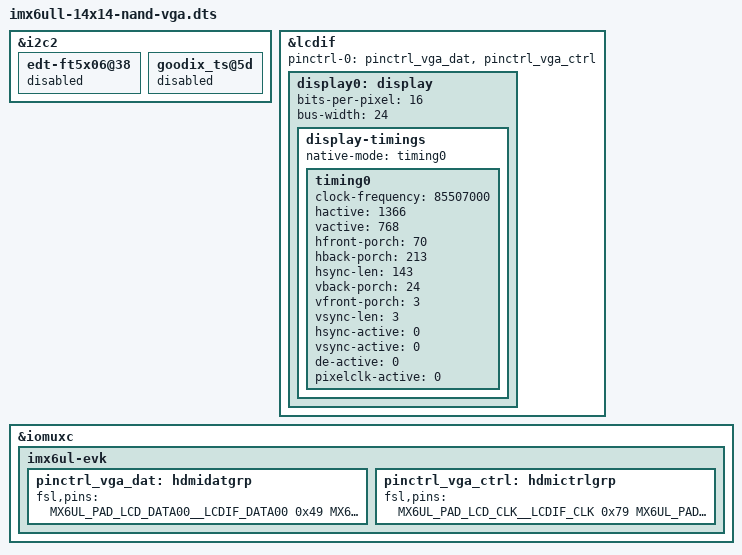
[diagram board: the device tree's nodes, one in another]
#include "imx6ull-14x14-evk-gpmi-weim.dts"

&i2c2 {
        edt-ft5x06@38 {
                status = "disabled";
        };

        goodix_ts@5d {
                status = "disabled";
        };
};

&lcdif {
        pinctrl-0 = <&pinctrl_vga_dat
                    &pinctrl_vga_ctrl>;

	display0: display {
		bits-per-pixel = <16>;
		bus-width = <24>;

		display-timings {
			native-mode = <&timing0>;
			timing0: timing0 {
                        clock-frequency = <85507000>;
                        hactive = <1366>;
                        vactive = <768>;
                        hfront-porch = <70>;
                        hback-porch = <213>;
                        hsync-len = <143>;
                        vback-porch = <24>;
                        vfront-porch = <3>;
                        vsync-len = <3>;

                        hsync-active = <0>;
                        vsync-active = <0>;
                        de-active = <0>;
                        pixelclk-active = <0>;
			};
		};
	};
};

&iomuxc {
	imx6ul-evk {
                pinctrl_vga_dat: hdmidatgrp {
                        fsl,pins = <
				/* do not change the pimux vlaue on alpaha and mini board*/
                                MX6UL_PAD_LCD_DATA00__LCDIF_DATA00  0x49
                                MX6UL_PAD_LCD_DATA01__LCDIF_DATA01  0x49
                                MX6UL_PAD_LCD_DATA02__LCDIF_DATA02  0x49
                                MX6UL_PAD_LCD_DATA03__LCDIF_DATA03  0x49
                                MX6UL_PAD_LCD_DATA04__LCDIF_DATA04  0x49
                                MX6UL_PAD_LCD_DATA05__LCDIF_DATA05  0x49
                                MX6UL_PAD_LCD_DATA06__LCDIF_DATA06  0x49
                                MX6UL_PAD_LCD_DATA07__LCDIF_DATA07  0x51
                                MX6UL_PAD_LCD_DATA08__LCDIF_DATA08  0x49
                                MX6UL_PAD_LCD_DATA09__LCDIF_DATA09  0x49
                                MX6UL_PAD_LCD_DATA10__LCDIF_DATA10  0x49
                                MX6UL_PAD_LCD_DATA11__LCDIF_DATA11  0x49
                                MX6UL_PAD_LCD_DATA12__LCDIF_DATA12  0x49
                                MX6UL_PAD_LCD_DATA13__LCDIF_DATA13  0x49
                                MX6UL_PAD_LCD_DATA14__LCDIF_DATA14  0x49
                                MX6UL_PAD_LCD_DATA15__LCDIF_DATA15  0x51
                                MX6UL_PAD_LCD_DATA16__LCDIF_DATA16  0x49
                                MX6UL_PAD_LCD_DATA17__LCDIF_DATA17  0x49
                                MX6UL_PAD_LCD_DATA18__LCDIF_DATA18  0x49
                                MX6UL_PAD_LCD_DATA19__LCDIF_DATA19  0x49
                                MX6UL_PAD_LCD_DATA20__LCDIF_DATA20  0x49
                                MX6UL_PAD_LCD_DATA21__LCDIF_DATA21  0x49
                                MX6UL_PAD_LCD_DATA22__LCDIF_DATA22  0x49
                                MX6UL_PAD_LCD_DATA23__LCDIF_DATA23  0x51
                        >;
                };

                pinctrl_vga_ctrl: hdmictrlgrp {
                        fsl,pins = <
                                MX6UL_PAD_LCD_CLK__LCDIF_CLK        0x79
                                MX6UL_PAD_LCD_ENABLE__LCDIF_ENABLE  0x79
                                MX6UL_PAD_LCD_HSYNC__LCDIF_HSYNC    0x79
                                MX6UL_PAD_LCD_VSYNC__LCDIF_VSYNC    0x79
                        >;
                };

	};
};


